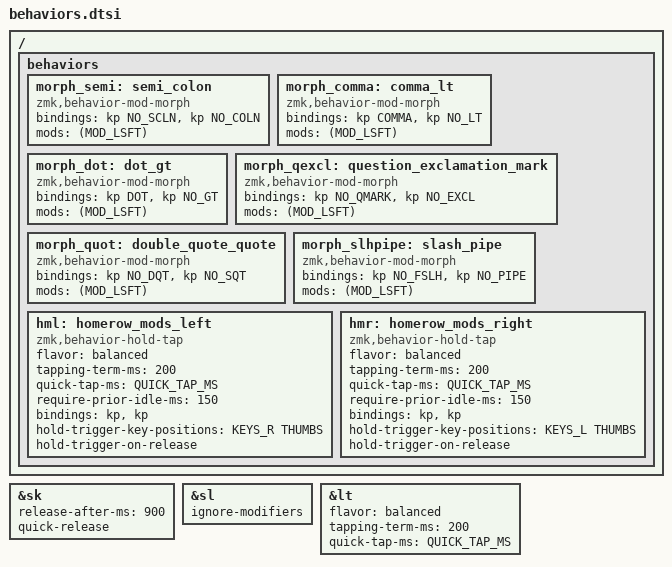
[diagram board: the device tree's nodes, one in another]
&sk { // sticky-key config
  release-after-ms = <900>;
  quick-release;
};

&sl { // sticky-layer config
  ignore-modifiers;
};

&lt { // layer-tap config
  flavor = "balanced";
  tapping-term-ms = <200>;
  quick-tap-ms = <QUICK_TAP_MS>;
};

/ {
  behaviors {
    morph_semi: semi_colon {
      compatible = "zmk,behavior-mod-morph";
      #binding-cells = <0>;
      bindings = <&kp NO_SCLN>, <&kp NO_COLN>;
      mods = <(MOD_LSFT)>;
    };

    morph_comma: comma_lt {
      compatible = "zmk,behavior-mod-morph";
      #binding-cells = <0>;
      bindings = <&kp COMMA>, <&kp NO_LT>;
      mods = <(MOD_LSFT)>;
    };

    morph_dot: dot_gt {
      compatible = "zmk,behavior-mod-morph";
      #binding-cells = <0>;
      bindings = <&kp DOT>, <&kp NO_GT>;
      mods = <(MOD_LSFT)>;
    };

    morph_qexcl: question_exclamation_mark {
      compatible = "zmk,behavior-mod-morph";
      #binding-cells = <0>;
      bindings = <&kp NO_QMARK>, <&kp NO_EXCL>;
      mods = <(MOD_LSFT)>;
    };

    morph_quot: double_quote_quote {
      compatible = "zmk,behavior-mod-morph";
      #binding-cells = <0>;
      bindings = <&kp NO_DQT>, <&kp NO_SQT>;
      mods = <(MOD_LSFT)>;
    };

    morph_slhpipe: slash_pipe {
      compatible = "zmk,behavior-mod-morph";
      #binding-cells = <0>;
      bindings = <&kp NO_FSLH>, <&kp NO_PIPE>;
      mods = <(MOD_LSFT)>;
    };

    hml: homerow_mods_left {
      compatible = "zmk,behavior-hold-tap";
      #binding-cells = <2>;
      flavor = "balanced";
      tapping-term-ms = <200>;
      quick-tap-ms = <QUICK_TAP_MS>;
      require-prior-idle-ms = <150>;
      bindings = <&kp>, <&kp>;
      hold-trigger-key-positions = <KEYS_R THUMBS>;
      hold-trigger-on-release;
    };

    hmr: homerow_mods_right {
      compatible = "zmk,behavior-hold-tap";
      #binding-cells = <2>;
      flavor = "balanced";
      tapping-term-ms = <200>;
      quick-tap-ms = <QUICK_TAP_MS>;
      require-prior-idle-ms = <150>;
      bindings = <&kp>, <&kp>;
      hold-trigger-key-positions = <KEYS_L THUMBS>;
      hold-trigger-on-release;
    };
  };
};
